# USART_0__I2C_Mode_1 register map
Vendor: Texas Instruments
Peripheral module from a debugger description file (folder msp430).
Registers are 8-bit, access not given, no defined reset value unless marked. A register's access mark holds for its fields unless they carry their own. Offsets are as the file gives them; lines under a group give offsets from that group; [hi:lo] are bit positions; {n}, {i} and the like mark numbered series; 'fields as' and 'values as' point back to an identical list; <NAME> marks a mode.

## USART_0_I2C_Mode
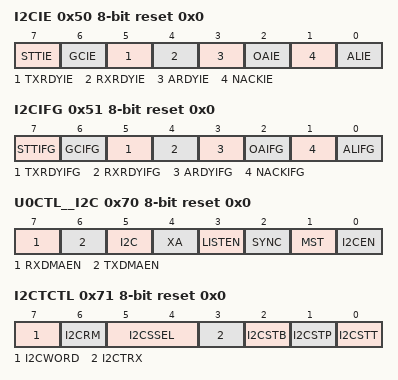
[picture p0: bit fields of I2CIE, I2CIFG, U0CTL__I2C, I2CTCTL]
0x50 I2CIE rw reset 0x0 — I2C Interrupt Enable
  [7] STTIE — Start condition
  [6] GCIE — General call
  [5] TXRDYIE — Transmit ready (transmit register empty)
  [4] RXRDYIE — Receive ready (data received)
  [3] ARDYIE — Access ready (opeation complete)
  [2] OAIE — Own address
  [1] NACKIE — No acknowledge
  [0] ALIE — Arbitration lost
0x51 I2CIFG rw reset 0x0 — I2C Interrupt Flag
  [7] STTIFG — Start condition
  [6] GCIFG — General call
  [5] TXRDYIFG — Transmit ready (transmit register empty)
  [4] RXRDYIFG — Receive ready (data received)
  [3] ARDYIFG — Access ready (opeation complete)
  [2] OAIFG — Own address
  [1] NACKIFG — No acknowledge
  [0] ALIFG — Arbitration lost
0x52 I2CNDAT — I2C Data Count
0x70 U0CTL__I2C rw reset 0x0 — USART 0 Control I2C
  [7] RXDMAEN — Receive DMA enable
  [6] TXDMAEN — Transmit DMA enable
  [5] I2C — USART I2C
  [4] XA — I2C extended addressing
  [3] LISTEN — Loopback
  [2] SYNC — USART synchronous/asynchronous
  [1] MST — I2C master
  [0] I2CEN — I2C enable
0x71 I2CTCTL rw reset 0x0 — I2C Transfer Control
  [7] I2CWORD — Word data mode
  [6] I2CRM — Repeat mode
  [5:4] I2CSSEL — Clock select bit 0
    0=I2C clock select 0: UCLK; 1=I2C clock select 1: ACLK; 2=I2C clock select 2: SMCLK; 3=I2C clock select 3: SMCLK
  [3] I2CTRX — Transmit
  [2] I2CSTB — Start byte mode
  [1] I2CSTP — Stop bit
  [0] I2CSTT — Start bit
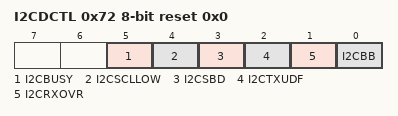
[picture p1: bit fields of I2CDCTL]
0x72 I2CDCTL rw reset 0x0 — I2C Data Control
  [5] I2CBUSY — I2C Busy Flag
  [4] I2CSCLLOW — SCL being held low
  [3] I2CSBD — Received byte
  [2] I2CTXUDF — Transmit underflow
  [1] I2CRXOVR — Receiver overrun
  [0] I2CBB — Bus busy
0x73 I2CPSC — I2C Pre-scaler
0x74 I2CSCLH — I2C SCL High
0x75 I2CSCLL — I2C SCL Low
0x76 I2CDRB — I2C Data for Byte access
0x76 I2CDRW 16-bit — I2C Data for Word access
0x118 I2COA 16-bit — I2C Own Address
0x11A I2CSA 16-bit — I2C Slave Address
0x11C I2CIV 16-bit — I2C Interrupt Vector
